# ATSAM4N16B device description
Architecture: CORTEX-M4; Family: SAM4; Series: SAM4N
Registers are 32-bit, read-write, no defined reset value unless marked. A register's access mark holds for its fields unless they carry their own. Offsets are from the block's base; [hi:lo] are bit positions; 'fields as' and 'values as' point back to an identical list.

## CHIPID — Chip Identifier
Instances: CHIPID 0x400E0740
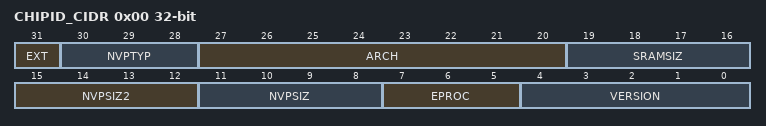
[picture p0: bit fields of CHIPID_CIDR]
0x00 CHIPID_CIDR ro — Chip ID Register
  [31] EXT — Extension Flag
  [30:28] NVPTYP — Nonvolatile Program Memory Type
    0=ROM; 1=ROMLESS (ROMless or on-chip Flash); 2=FLASH (Embedded Flash Memory); 3=ROM_FLASH (ROM and Embedded Flash Memory- NVPSIZ is ROM size- NVPSIZ2 is Flash size); 4=SRAM (SRAM emulating ROM)
  [27:20] ARCH — Architecture Identifier
    25=AT91SAM9xx Series; 41=AT91SAM9XExx Series; 52=AT91x34 Series; 55=CAP7 (CAP7 Series); 57=CAP9 (CAP9 Series); 59=CAP11 (CAP11 Series); 64=AT91x40 Series; 66=AT91x42 Series; 69=AT91SAM4SH2 (AT91SAM4SH2 Series); 85=AT91x55 Series; 96=AT91SAM7Axx Series; 97=AT91SAM7AQxx Series; 99=AT91x63 Series; 100=SAM4CxxC (SAM4CxC Series (100-pin version)); 102=SAM4CxxE (SAM4CxE Series (144-pin version)); 112=AT91SAM7Sxx Series; 113=AT91SAM7XCxx Series; 114=AT91SAM7SExx Series; 115=AT91SAM7Lxx Series; 117=AT91SAM7Xxx Series; 118=AT91SAM7SLxx Series; 128=SAM3UxC Series (100-pin version); 129=SAM3UxE Series (144-pin version); 131=SAM3AxC Series (100-pin version); 132=SAM3XxC Series (100-pin version); 133=SAM3XxE Series (144-pin version); 134=SAM3XxG Series (208/217-pin version); 146=AT91x92 Series; 147=SAM4NxA Series (48-pin version); 148=SAM4NxB Series (64-pin version); 149=SAM4NxC Series (100-pin version); 153=SAM3SDxB Series (64-pin version); 154=SAM3SDxC Series (100-pin version); 165=SAM5A; 176=SAM4LxA Series (48-pin version); 177=SAM4LxB Series (64-pin version); 178=SAM4LxC Series (100-pin version); 240=AT75Cxx Series
  [19:16] SRAMSIZ — Internal SRAM Size
    0=_48K (48 Kbytes); 1=_192K (192 Kbytes); 2=_2K (2 Kbytes); 3=_6K (6 Kbytes); 4=_24K (24 Kbytes); 5=_4K (4 Kbytes); 6=_80K (80 Kbytes); 7=_160K (160 Kbytes); 8=_8K (8 Kbytes); 9=_16K (16 Kbytes); 10=_32K (32 Kbytes); 11=_64K (64 Kbytes); 12=_128K (128 Kbytes); 13=_256K (256 Kbytes); 14=_96K (96 Kbytes); 15=_512K (512 Kbytes)
  [15:12] NVPSIZ2 — Second Nonvolatile Program Memory Size
    0=NONE; 1=_8K (8 Kbytes); 2=_16K (16 Kbytes); 3=_32K (32 Kbytes); 5=_64K (64 Kbytes); 7=_128K (128 Kbytes); 9=_256K (256 Kbytes); 10=_512K (512 Kbytes); 12=_1024K (1024 Kbytes); 14=_2048K (2048 Kbytes)
  [11:8] NVPSIZ — Nonvolatile Program Memory Size
    values as NVPSIZ2
  [7:5] EPROC — Embedded Processor
    1=ARM946ES; 2=ARM7TDMI; 3=CM3 (Cortex-M3); 4=ARM920T; 5=ARM926EJS; 6=CA5 (Cortex-A5); 7=CM4 (Cortex-M4)
  [4:0] VERSION — Version of the Device
0x04 CHIPID_EXID ro — Chip ID Extension Register
  [31:0] EXID — Chip ID Extension

## DACC — Digital-to-Analog Converter Controller
Instances: DACC 0x4003C000
0x00 DACC_CR wo — Control Register
  [0] SWRST — Software Reset
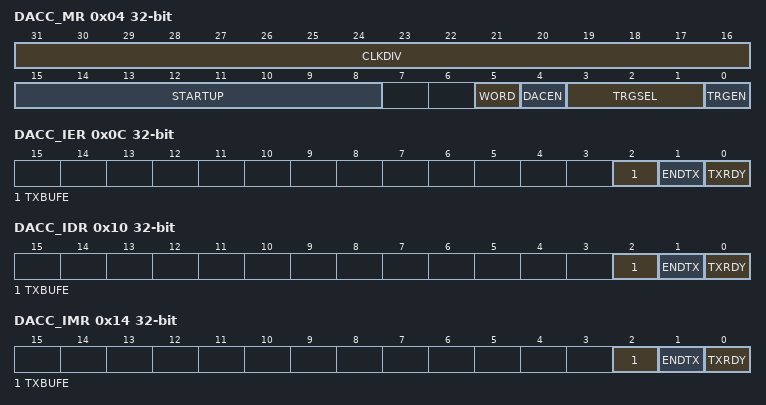
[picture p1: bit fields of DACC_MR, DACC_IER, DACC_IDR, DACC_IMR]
0x04 DACC_MR — Mode Register
  [31:16] CLKDIV — DAC Clock Divider for Internal Trigger
  [15:8] STARTUP — Start-up Time Selection
  [5] WORD — Word Transfer
    0=HALF_WORD (Half-Word transfer.); 1=WORD (Word Transfer.)
  [4] DACEN — DAC enable
    0=DISABLED (DAC disabled.); 1=ENABLED (DAC enabled.)
  [3:1] TRGSEL — Trigger Selection
    0=External trigger; 1=TIO Output of the Timer Counter Channel 0; 2=TIO Output of the Timer Counter Channel 1; 3=TIO Output of the Timer Counter Channel 2
  [0] TRGEN — Trigger Enable
    0=FREE_RUN (External trigger mode disabled. DACC in free running mode.); 1=EXT_TRIG (External trigger mode enabled.)
0x08 DACC_CDR wo — Conversion Data Register
  [31:0] DATA — Data to Convert
0x0C DACC_IER wo — Interrupt Enable Register
  [2] TXBUFE — Buffer Empty Interrupt Enable
  [1] ENDTX — End of PDC Interrupt Enable
  [0] TXRDY — Transmission Ready Interrupt Enable
0x10 DACC_IDR wo — Interrupt Disable Register
  [2] TXBUFE — Buffer Empty Interrupt Disable
  [1] ENDTX — End of PDC Interrupt Disable
  [0] TXRDY — Transmission Ready Interrupt Disable
0x14 DACC_IMR ro — Interrupt Mask Register
  [2] TXBUFE — Buffer Empty Interrupt Mask
  [1] ENDTX — End of PDC Interrupt Mask
  [0] TXRDY — Transmission Ready Interrupt Mask
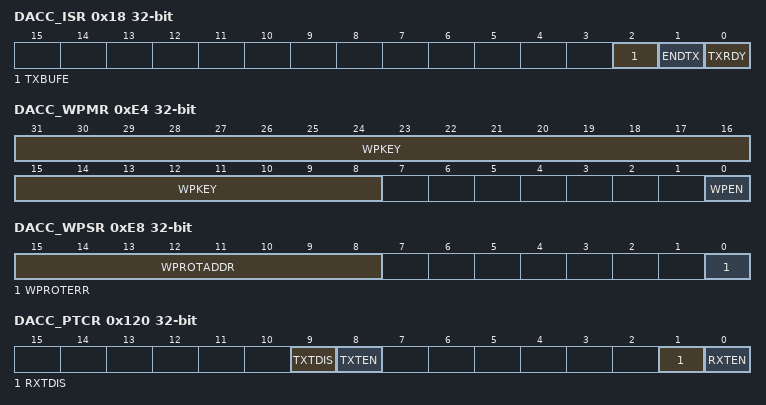
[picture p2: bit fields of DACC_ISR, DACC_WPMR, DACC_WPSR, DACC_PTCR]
0x18 DACC_ISR ro — Interrupt Status Register
  [2] TXBUFE — Buffer Empty Interrupt Flag
  [1] ENDTX — End of PDC Interrupt Flag
  [0] TXRDY — Transmission Ready Interrupt Flag
0xE4 DACC_WPMR — Write Protect Mode Register
  [31:8] WPKEY — Write Protect KEY
    0x444143=PASSWD (Writing any other value in this field aborts the write operation of the WPEN bit.Always reads as 0.)
  [0] WPEN — Write Protect Enable
0xE8 DACC_WPSR ro — Write Protect Status Register
  [15:8] WPROTADDR — Write protection error address
  [0] WPROTERR — Write protection error
0x108 DACC_TPR — Transmit Pointer Register
  [31:0] TXPTR — Transmit Counter Register
0x10C DACC_TCR — Transmit Counter Register
  [15:0] TXCTR
0x118 DACC_TNPR — Transmit Next Pointer Register
  [31:0] TXNPTR — Transmit Next Pointer
0x11C DACC_TNCR — Transmit Next Counter Register
  [15:0] TXNCTR — Transmit Counter Next
0x120 DACC_PTCR wo — Transfer Control Register
  [9] TXTDIS — Transmitter Transfer Disable
  [8] TXTEN — Transmitter Transfer Enable
  [1] RXTDIS — Receiver Transfer Disable
  [0] RXTEN — Receiver Transfer Enable
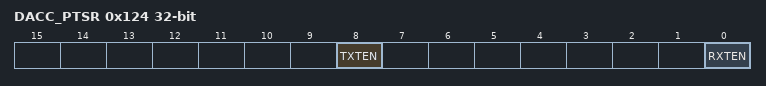
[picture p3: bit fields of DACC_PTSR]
0x124 DACC_PTSR ro — Transfer Status Register
  [8] TXTEN — Transmitter Transfer Enable
  [0] RXTEN — Receiver Transfer Enable

## Notices in the file
SAM Software Package License
Copyright (c) %copyright_year%, Atmel Corporation
All rights reserved.
Redistribution and use in source and binary forms, with or without
modification, are permitted provided that the following condition is met:
- Redistributions of source code must retain the above copyright notice,
this list of conditions and the disclaimer below.
Atmel's name may not be used to endorse or promote products derived from
this software without specific prior written permission.
DISCLAIMER:  THIS SOFTWARE IS PROVIDED BY ATMEL "AS IS" AND ANY EXPRESS OR
IMPLIED WARRANTIES, INCLUDING, BUT NOT LIMITED TO, THE IMPLIED WARRANTIES OF
MERCHANTABILITY, FITNESS FOR A PARTICULAR PURPOSE AND NON-INFRINGEMENT ARE
DISCLAIMED. IN NO EVENT SHALL ATMEL BE LIABLE FOR ANY DIRECT, INDIRECT,
INCIDENTAL, SPECIAL, EXEMPLARY, OR CONSEQUENTIAL DAMAGES (INCLUDING, BUT NOT
LIMITED TO, PROCUREMENT OF SUBSTITUTE GOODS OR SERVICES; LOSS OF USE, DATA,
OR PROFITS; OR BUSINESS INTERRUPTION) HOWEVER CAUSED AND ON ANY THEORY OF
LIABILITY, WHETHER IN CONTRACT, STRICT LIABILITY, OR TORT (INCLUDING
NEGLIGENCE OR OTHERWISE) ARISING IN ANY WAY OUT OF THE USE OF THIS SOFTWARE,
EVEN IF ADVISED OF THE POSSIBILITY OF SUCH DAMAGE.
